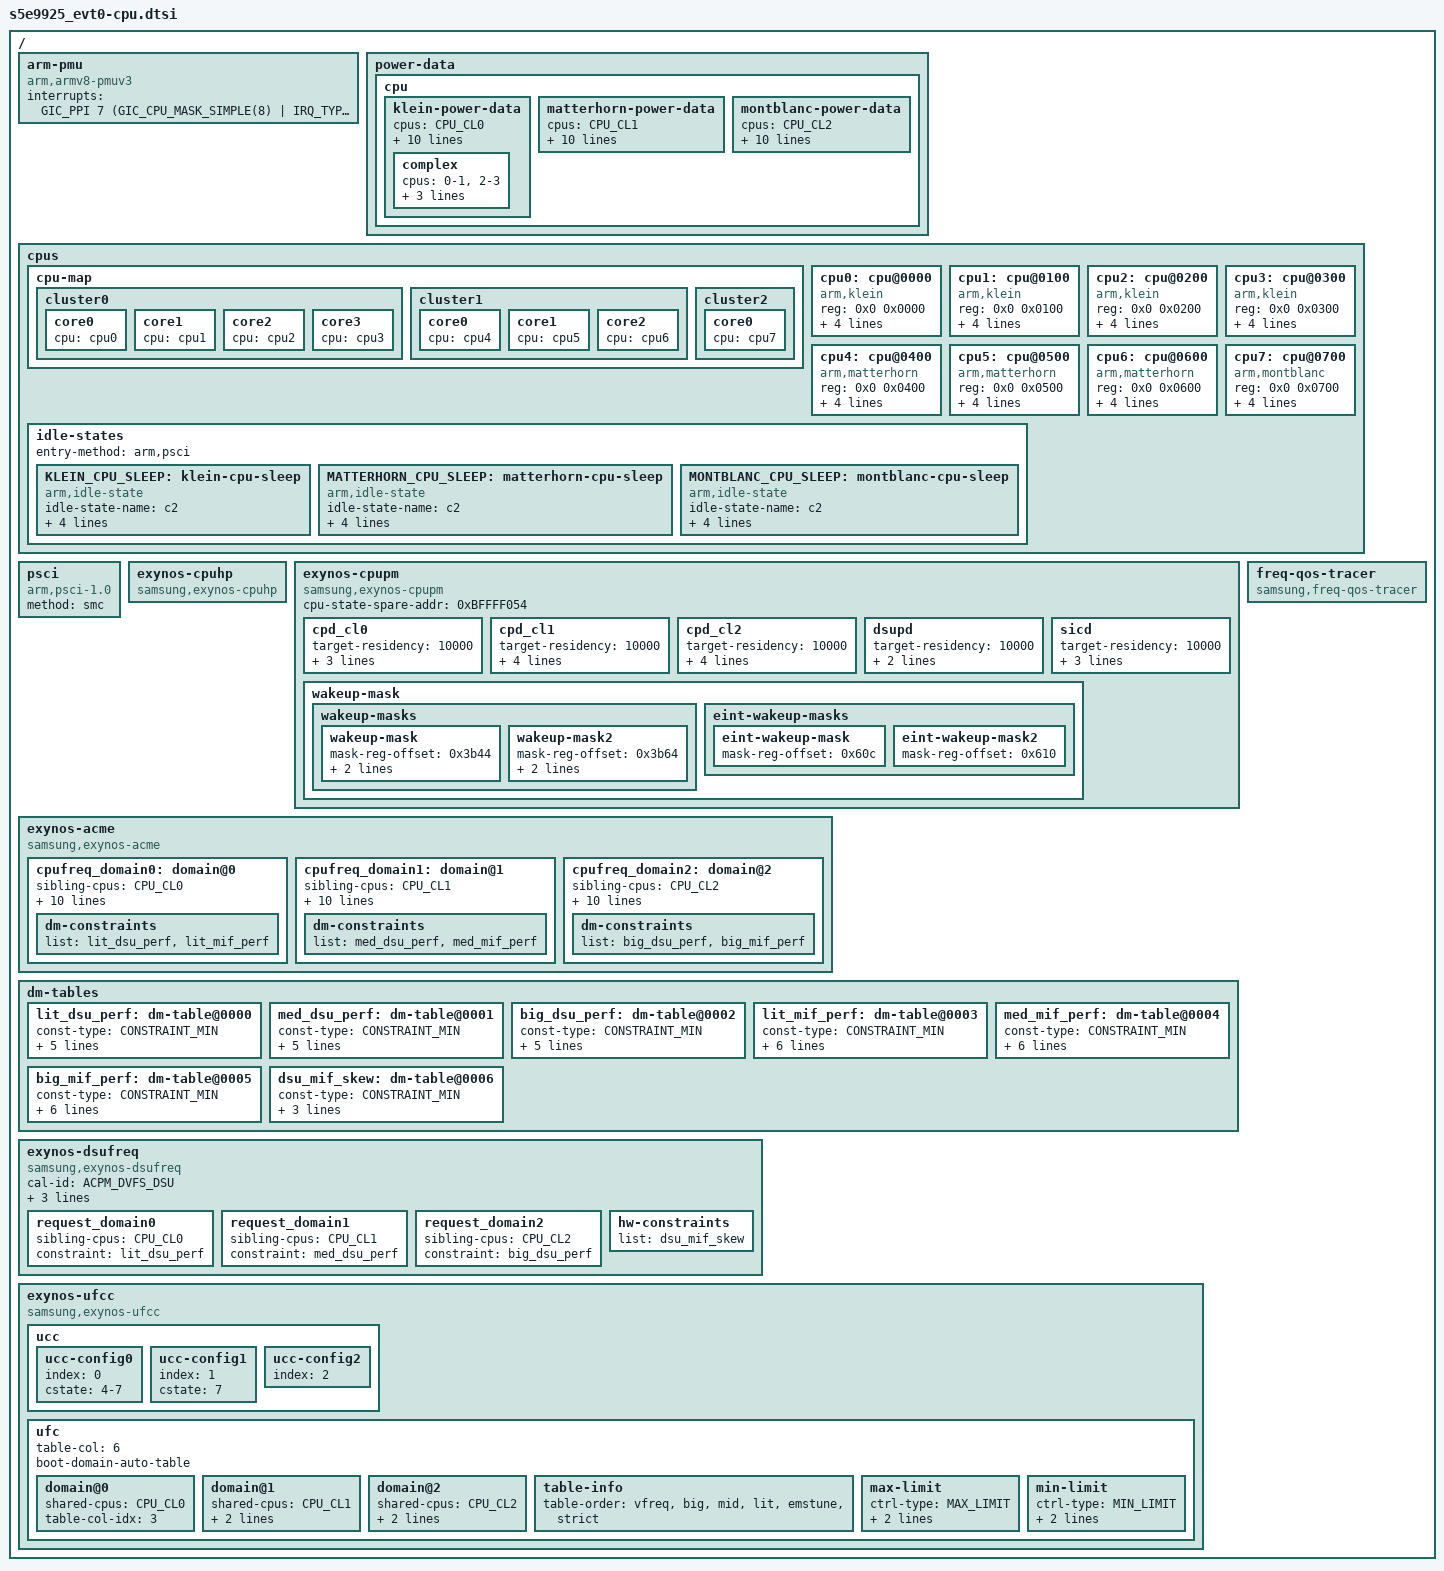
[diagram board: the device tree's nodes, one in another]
/*
 * SAMSUNG S5E9925 SoC CPU device tree source
 *
 * Copyright (c) 2020 Samsung Electronics Co., Ltd.
 *             http://www.samsung.com
 *
 * SAMSUNG EXYNOS9925 SoC device nodes are listed in this file.
 * EXYNOS based board files can include this file and provide
 * values for board specfic bindings.
 *
 * This program is free software; you can redistribute it and/or modify
 * it under the terms of the GNU General Public License version 2 as
 * published by the Free Software Foundation.
 */

#include <dt-bindings/soc/samsung/cpupm.h>

/ {
	arm-pmu {
		compatible = "arm,armv8-pmuv3";
		interrupts = <GIC_PPI 7 (GIC_CPU_MASK_SIMPLE(8) | IRQ_TYPE_LEVEL_HIGH)>;
	};

	#define CPU_CL0	"0-3"
	#define CPU_CL1	"4-6"
	#define CPU_CL2	"7"
	#define CPU_ALL	"0-7"

	power-data {
		#define CPUCL0_DMIPS_PER_MHZ 378
		#define CPUCL1_DMIPS_PER_MHZ 880
		#define CPUCL2_DMIPS_PER_MHZ 1005

		#define CPUCL0_DP_COEFF	188
		#define CPUCL1_DP_COEFF	482
		#define CPUCL2_DP_COEFF	710

		#define CPUCL0_SP_COEFF	62
		#define CPUCL1_SP_COEFF	234
		#define CPUCL2_SP_COEFF	537

		cpu {
			klein-power-data {
				/* default power data */
				cpus = CPU_CL0;
				capacity-dmips-mhz = <CPUCL0_DMIPS_PER_MHZ>;
				dynamic-power-coefficient = <CPUCL0_DP_COEFF>;
				static-power-coefficient = <CPUCL0_SP_COEFF>;

				/* dynamic power w/ ECT */
				ect-coeff-idx = <2>;

				/* precise static power */
				cal-id = <ACPM_DVFS_CPUCL0>;
				ect-param-vt = "DTM_LIT_VOLT_TEMP";
				ect-param-asv = "DTM_LIT_ASV";
				tz-name = "LITTLE";

				/* dhrystone to clang conversion ratio */
				dhry-to-clang-dp-ratio = <820>;
				dhry-to-clang-cap-ratio = <538>;

				complex {
					cpus = "0-1", "2-3";

					/* complex core/shared ratio */
					ect-param-cr = "COMPLEX_RATIO";
					ect-param-ccr = "COMPLEX_CORE_RATIO";
					ect-param-csr = "COMPLEX_SHARED_RATIO";
				};
			};
			matterhorn-power-data {
				/* default power data */
				cpus = CPU_CL1;
				capacity-dmips-mhz = <CPUCL1_DMIPS_PER_MHZ>;
				dynamic-power-coefficient = <CPUCL1_DP_COEFF>;
				static-power-coefficient = <CPUCL1_SP_COEFF>;

				/* dynamic power w/ ECT */
				ect-coeff-idx = <1>;

				/* precise static power */
				cal-id = <ACPM_DVFS_CPUCL1>;
				ect-param-vt = "DTM_MID_VOLT_TEMP";
				ect-param-asv = "DTM_MID_ASV";
				tz-name = "MID";

				/* dhrystone to clang conversion ratio */
				dhry-to-clang-dp-ratio = <820>;
				dhry-to-clang-cap-ratio = <377>;
			};
			montblanc-power-data {
				/* default power data */
				cpus = CPU_CL2;
				capacity-dmips-mhz = <CPUCL2_DMIPS_PER_MHZ>;
				dynamic-power-coefficient = <CPUCL2_DP_COEFF>;
				static-power-coefficient = <CPUCL2_SP_COEFF>;

				/* dynamic power w/ ECT */
				ect-coeff-idx = <0>;

				/* precise static power */
				cal-id = <ACPM_DVFS_CPUCL2>;
				ect-param-vt = "DTM_BIG_VOLT_TEMP";
				ect-param-asv = "DTM_BIG_ASV";
				tz-name = "BIG";

				/* dhrystone to clang conversion ratio */
				dhry-to-clang-dp-ratio = <820>;
				dhry-to-clang-cap-ratio = <385>;
			};
		};
	};

	cpus {
		#address-cells = <2>;
		#size-cells = <0>;

		cpu-map {
			cluster0 {
				core0 {
					cpu = <&cpu0>;
				};
				core1 {
					cpu = <&cpu1>;
				};
				core2 {
					cpu = <&cpu2>;
				};
				core3 {
					cpu = <&cpu3>;
				};
			};
			cluster1 {
				core0 {
					cpu = <&cpu4>;
				};
				core1 {
					cpu = <&cpu5>;
				};
				core2 {
					cpu = <&cpu6>;
				};
			};
			cluster2 {
				core0 {
					cpu = <&cpu7>;
				};
			};
		};

		cpu0: cpu@0000 {
			device_type = "cpu";
			compatible = "arm,klein", "arm,armv9";
			reg = <0x0 0x0000>;
			capacity-dmips-mhz = <CPUCL0_DMIPS_PER_MHZ>;
			dynamic-power-coefficient = <CPUCL0_DP_COEFF>;
			enable-method = "psci";
			cpu-idle-states =  <&KLEIN_CPU_SLEEP>;
		};
		cpu1: cpu@0100 {
			device_type = "cpu";
			compatible = "arm,klein", "arm,armv9";
			reg = <0x0 0x0100>;
			capacity-dmips-mhz = <CPUCL0_DMIPS_PER_MHZ>;
			dynamic-power-coefficient = <CPUCL0_DP_COEFF>;
			enable-method = "psci";
			cpu-idle-states =  <&KLEIN_CPU_SLEEP>;
		};
		cpu2: cpu@0200 {
			device_type = "cpu";
			compatible = "arm,klein", "arm,armv9";
			reg = <0x0 0x0200>;
			capacity-dmips-mhz = <CPUCL0_DMIPS_PER_MHZ>;
			dynamic-power-coefficient = <CPUCL0_DP_COEFF>;
			enable-method = "psci";
			cpu-idle-states =  <&KLEIN_CPU_SLEEP>;
		};
		cpu3: cpu@0300 {
			device_type = "cpu";
			compatible = "arm,klein", "arm,armv9";
			reg = <0x0 0x0300>;
			capacity-dmips-mhz = <CPUCL0_DMIPS_PER_MHZ>;
			dynamic-power-coefficient = <CPUCL0_DP_COEFF>;
			enable-method = "psci";
			cpu-idle-states =  <&KLEIN_CPU_SLEEP>;
		};
		cpu4: cpu@0400 {
			device_type = "cpu";
			compatible = "arm,matterhorn", "arm,armv9";
			reg = <0x0 0x0400>;
			capacity-dmips-mhz = <CPUCL1_DMIPS_PER_MHZ>;
			dynamic-power-coefficient = <CPUCL1_DP_COEFF>;
			enable-method = "psci";
			cpu-idle-states =  <&MATTERHORN_CPU_SLEEP>;
		};
		cpu5: cpu@0500 {
			device_type = "cpu";
			compatible = "arm,matterhorn", "arm,armv9";
			reg = <0x0 0x0500>;
			capacity-dmips-mhz = <CPUCL1_DMIPS_PER_MHZ>;
			dynamic-power-coefficient = <CPUCL1_DP_COEFF>;
			enable-method = "psci";
			cpu-idle-states =  <&MATTERHORN_CPU_SLEEP>;
		};
		cpu6: cpu@0600 {
			device_type = "cpu";
			compatible = "arm,matterhorn", "arm,armv9";
			reg = <0x0 0x0600>;
			capacity-dmips-mhz = <CPUCL1_DMIPS_PER_MHZ>;
			dynamic-power-coefficient = <CPUCL1_DP_COEFF>;
			enable-method = "psci";
			cpu-idle-states =  <&MATTERHORN_CPU_SLEEP>;
		};
		cpu7: cpu@0700 {
			device_type = "cpu";
			compatible = "arm,montblanc", "arm,armv9";
			reg = <0x0 0x0700>;
			capacity-dmips-mhz = <CPUCL2_DMIPS_PER_MHZ>;
			dynamic-power-coefficient = <CPUCL2_DP_COEFF>;
			enable-method = "psci";
			cpu-idle-states =  <&MONTBLANC_CPU_SLEEP>;
		};

		idle-states {
			entry-method = "arm,psci";

			KLEIN_CPU_SLEEP: klein-cpu-sleep {
				idle-state-name = "c2";
				compatible = "arm,idle-state";
				arm,psci-suspend-param = <0x0010000>;
				entry-latency-us = <70>;
				exit-latency-us = <160>;
				min-residency-us = <2000>;
				status = "okay";
			};

			MATTERHORN_CPU_SLEEP: matterhorn-cpu-sleep {
				idle-state-name = "c2";
				compatible = "arm,idle-state";
				arm,psci-suspend-param = <0x0010000>;
				entry-latency-us = <150>;
				exit-latency-us = <190>;
				min-residency-us = <2500>;
				status = "okay";
			};

			MONTBLANC_CPU_SLEEP: montblanc-cpu-sleep {
				idle-state-name = "c2";
				compatible = "arm,idle-state";
				arm,psci-suspend-param = <0x0010000>;
				entry-latency-us = <235>;
				exit-latency-us = <220>;
				min-residency-us = <3500>;
				status = "okay";
			};

		};

	};

	psci {
		compatible = "arm,psci-1.0";
		method = "smc";
	};

	exynos-cpuhp {
		compatible = "samsung,exynos-cpuhp";
		status = "okay";
	};

	exynos-cpupm {
		compatible = "samsung,exynos-cpupm";
		status = "okay";
		cpu-state-spare-addr = <0xBFFFF054>;

		cpd_cl0 {
			device_type ="cpupm";
			target-residency = <10000>;
			type = <POWERMODE_TYPE_CLUSTER>;
			cal-id = <0>;
			siblings = CPU_CL0;
		};

		cpd_cl1 {
			device_type = "cpupm";
			target-residency = <10000>;
			type = <POWERMODE_TYPE_CLUSTER>;
			cal-id = <1>;
			siblings = CPU_CL1;
			entry-allowed = CPU_CL1;
		};

		cpd_cl2 {
			device_type = "cpupm";
			target-residency = <10000>;
			type = <POWERMODE_TYPE_CLUSTER>;
			cal-id = <2>;
			siblings = CPU_CL2;
			entry-allowed = CPU_CL2;
		};

		dsupd {
			device_type = "cpupm";
			target-residency = <10000>;
			type = <POWERMODE_TYPE_DSU>;
			siblings = CPU_ALL;
		};

		sicd {
			device_type = "cpupm";
			target-residency = <10000>;
			type = <POWERMODE_TYPE_SYSTEM>;
			siblings = CPU_ALL;
			entry-allowed = CPU_ALL;
		};

		wakeup-mask {
			wakeup-masks {
				wakeup-mask {
					mask-reg-offset = <0x3b44>;
					stat-reg-offset = <0x3b50>;
					mask = <0xff000000>;
				};
				wakeup-mask2 {
					mask-reg-offset = <0x3b64>;
					stat-reg-offset = <0x3b54>;
					mask = <0x00>;
				};
			};

			eint-wakeup-masks {
				eint-wakeup-mask {
					mask-reg-offset = <0x60c>;
				};
				eint-wakeup-mask2 {
					mask-reg-offset = <0x610>;
				};
			};
		};
	};

	exynos-acme {
		compatible = "samsung,exynos-acme";
		status = "okay";

		cpufreq_domain0: domain@0 {
			sibling-cpus = CPU_CL0;
			cal-id = <ACPM_DVFS_CPUCL0>;
			dm-type = <DM_CPU_CL0>;

			max-freq = <2112000>;
			min-freq = <400000>;

			fast-switch;
			thread-run-on = "0-5";

			#cooling-cells = <2>; /* min followed by max */
			ect-coeff-index = <2>;
			tz-cooling-name = "LITTLE";

			freq-table = < 160000
				       267000
				       400000
				       576000
				       768000
				       960000
				      1152000
				      1344000
				      1536000
				      1728000
				      1920000
				      2112000
				      2304000
				      2400000
				      2516000
				      2612000 >;

			dm-constraints {
				list = <&lit_dsu_perf>,
					<&lit_mif_perf>;
			};
		};

		cpufreq_domain1: domain@1 {
			sibling-cpus = CPU_CL1;
			cal-id = <ACPM_DVFS_CPUCL1>;
			dm-type = <DM_CPU_CL1>;

			max-freq = <2880000>;
			min-freq = <576000>;

			fast-switch;
			thread-run-on = "0-5";

			#cooling-cells = <2>; /* min followed by max */
			ect-coeff-index = <1>;
			tz-cooling-name = "MID";

			freq-table = < 160000
				       267000
				       400000
				       576000
				       768000
				       960000
				      1152000
				      1344000
				      1536000
				      1728000
				      1920000
				      2112000
				      2304000
				      2496000
				      2688000
				      2880000
				      2912000
				      3015000
				      3111000
				      3207000 >;

			dm-constraints {
				list = <&med_dsu_perf>,
					<&med_mif_perf>;
			};
		};

		cpufreq_domain2: domain@2 {
			sibling-cpus = CPU_CL2;
			cal-id = <ACPM_DVFS_CPUCL2>;
			dm-type = <DM_CPU_CL2>;

			max-freq = <2912000>;
			min-freq = <576000>;

			fast-switch;
			thread-run-on = "0-5";

			#cooling-cells = <2>; /* min followed by max */
			ect-coeff-index = <0>;
			tz-cooling-name = "BIG";

			freq-table = < 160000
				       267000
				       400000
				       576000
				       768000
				       960000
				      1152000
				      1344000
				      1536000
				      1728000
				      1920000
				      2112000
				      2304000
				      2496000
				      2688000
				      2880000
				      2912000
				      3015000
				      3110000
				      3207000 >;

			dm-constraints {
				list = <&big_dsu_perf>,
					<&big_mif_perf>;
			};
		};
	};

	dm-tables {
		lit_dsu_perf: dm-table@0000 {
			const-type = <CONSTRAINT_MIN>;
			dm-slave = <DM_DSU>;
			master-cal-id = <ACPM_DVFS_CPUCL0>;
			slave-cal-id = <ACPM_DVFS_DSU>;

				/* CPU	  DSU */
			table = < 160000  160000
				  267000  160000
				  400000  267000
				  576000  267000
				  768000  480000
				  960000  672000
				 1152000  864000
				 1344000 1056000
				 1536000 1248000
				 1728000 1440000
				 1920000 1632000
				 2112000 1824000
				 2304000 2016000
				 2400000 2112000
				 2516000 2112000
				 2612000 2208000 >;
		};
		med_dsu_perf: dm-table@0001 {
			const-type = <CONSTRAINT_MIN>;
			dm-slave = <DM_DSU>;
			master-cal-id = <ACPM_DVFS_CPUCL1>;
			slave-cal-id = <ACPM_DVFS_DSU>;

				/* CPU	  DSU */
			table = < 160000  160000
				  267000  160000
				  400000  267000
				  576000  267000
				  768000  480000
				  960000  672000
				 1152000  864000
				 1344000  864000
				 1536000 1056000
				 1728000 1248000
				 1920000 1440000
				 2112000 1632000
				 2304000 1824000
				 2496000 2016000
				 2688000 2016000
				 2880000 2112000
				 3015000 2208000
				 3111000 2208000
				 3207000 2208000 >;
		};
		big_dsu_perf: dm-table@0002 {
			const-type = <CONSTRAINT_MIN>;
			dm-slave = <DM_DSU>;
			master-cal-id = <ACPM_DVFS_CPUCL2>;
			slave-cal-id = <ACPM_DVFS_DSU>;

				/* CPU	  DSU */
			table = < 166000  166000
				  267000  166000
				  400000  267000
				  576000  267000
				  768000  480000
				  960000  672000
				 1152000  672000
				 1248000  864000
				 1344000  864000
				 1536000 1056000
				 1728000 1248000
				 1920000 1440000
				 2112000 1632000
				 2304000 1632000
				 2496000 1824000
				 2688000 2016000
				 2880000 2112000
				 2912000 2112000
				 3015000 2208000
				 3110000 2208000
				 3207000 2208000 >;
		};
		lit_mif_perf: dm-table@0003 {
			const-type = <CONSTRAINT_MIN>;
			dm-slave = <DM_MIF>;
			master-cal-id = <ACPM_DVFS_CPUCL0>;
			slave-cal-id = <ACPM_DVFS_MIF>;
			dynamic-disable;

				/* CPU	  MIF */
			table = < 160000       0
				  267000       0
				  400000       0
				  576000       0
				  768000       0
				  960000       0
				 1152000       0
				 1344000       0
				 1536000       0
				 1728000       0
				 1920000       0
				 2112000       0
				 2304000       0
				 2400000       0
				 2516000       0
				 2612000       0 >;
		};
		med_mif_perf: dm-table@0004 {
			const-type = <CONSTRAINT_MIN>;
			dm-slave = <DM_MIF>;
			master-cal-id = <ACPM_DVFS_CPUCL1>;
			slave-cal-id = <ACPM_DVFS_MIF>;
			dynamic-disable;

				/* CPU	  MIF */
			table = < 160000       0
				  267000       0
				  400000       0
				  576000       0
				  768000       0
				  960000       0
				 1152000       0
				 1344000       0
				 1536000       0
				 1728000       0
				 1920000       0
				 2112000       0
				 2304000       0
				 2496000       0
				 2688000       0
				 2880000       0
				 3015000       0
				 3111000       0
				 3207000       0 >;
		};
		big_mif_perf: dm-table@0005 {
			const-type = <CONSTRAINT_MIN>;
			dm-slave = <DM_MIF>;
			master-cal-id = <ACPM_DVFS_CPUCL2>;
			slave-cal-id = <ACPM_DVFS_MIF>;
			dynamic-disable;

				/* CPU	  MIF */
			table = < 160000       0
				  267000       0
				  400000       0
				  576000       0
				  768000       0
				  960000       0
				 1152000       0
				 1344000       0
				 1536000       0
				 1728000       0
				 1920000       0
				 2112000       0
				 2304000       0
				 2496000       0
				 2688000       0
				 2880000       0
				 3015000       0
				 3110000       0
				 3207000       0 >;
		};
		dsu_mif_skew: dm-table@0006 {
			const-type = <CONSTRAINT_MIN>;
			dm-slave = <DM_MIF>;
			ect-name = "DSU_MIF";
			guidance;
		};
	};

	exynos-dsufreq {
		compatible = "samsung,exynos-dsufreq";
		status = "okay";

		cal-id = <ACPM_DVFS_DSU>;
		dm-type = <DM_DSU>;
		dss-type = <ESS_FLAG_DSU>;
		init-with-dt = <1>;

		request_domain0 {
			sibling-cpus = CPU_CL0;
			constraint = <&lit_dsu_perf>;
		};
		request_domain1 {
			sibling-cpus = CPU_CL1;
			constraint = <&med_dsu_perf>;
		};
		request_domain2 {
			sibling-cpus = CPU_CL2;
			constraint = <&big_dsu_perf>;
		};
		hw-constraints {
			list = <&dsu_mif_skew>;
		};
	};

	exynos-ufcc {
		compatible = "samsung,exynos-ufcc";
		status = "okay";

		ucc {
			ucc-config0 {
				index = <0>;
				cstate = "4-7";
			};
			ucc-config1 {
				index = <1>;
				cstate = "7";
			};
			ucc-config2 {
				index = <2>;
			};
		};

		ufc {
			/* Ctrl Type */
			#define MIN_LIMIT		0
			#define MIN_LIMIT_WO_BOOST	1
			#define MAX_LIMIT		2

			table-col = <6>;
			boot-domain-auto-table;

			domain@0 {
				device_type = "ufc-domain";
				shared-cpus = CPU_CL0;
				table-col-idx = <3>;
			};
			domain@1 {
				device_type = "ufc-domain";
				shared-cpus = CPU_CL1;
				table-col-idx = <2>;
				allow-disable-cpus;
			};
			domain@2 {
				device_type = "ufc-domain";
				shared-cpus = CPU_CL2;
				table-col-idx = <1>;
				allow-disable-cpus;
			};

			table-info {
				table-order = "vfreq",
					"big",
					"mid",
					"lit",
					"emstune",
					"strict";
			};

			max-limit {
				device_type = "ufc-table";
				ctrl-type = <MAX_LIMIT>;

				table = < 3207000 3207000 3207000 2304000 0 0
					  3111000 3111000 3111000 2304000 0 0
					  3015000 3015000 3015000 2304000 0 0
					  2912000 2912000 2912000 2304000 0 0
					  2880000 2880000 2880000 2304000 0 0
					  2688000 2688000 2688000 2304000 0 0
					  2496000 2496000 2496000 2304000 0 0
					  2304000 2304000 2304000 2304000 0 0
					  2112000 2112000 2112000 2304000 0 0
					  1920000 1920000 1920000 2304000 0 0
					  1728000 1728000 1728000 2112000 0 0
					  1536000 1536000 1536000 1920000 0 0
					  1344000 1344000 1344000 1728000 0 0
					  1152000 1152000 1152000 1536000 0 0
					   960000  960000  960000 1344000 0 0
					   768000  768000  768000 1152000 0 0
					   576000  576000  576000 1152000 0 0
					   400000  400000  400000 1152000 0 0 >;
					  /* fill little freq automatically */
			};
			min-limit {
				device_type = "ufc-table";
				ctrl-type = <MIN_LIMIT>;

				table = < 3207000 3207000 3207000 2612000 2 1
					  3111000 3111000 3111000 2612000 2 1
					  3015000 3015000 3015000 2612000 2 1
					  2912000 2912000 2912000 2612000 2 1
					  2880000 2880000 2880000 2612000 2 1
					  2688000 2688000 2688000 2612000 2 1
					  2496000 2496000 2496000 2612000 2 1
					  2304000 2304000 2304000 2612000 2 1
					  2112000 2112000 2112000  768000 1 1
					  1920000 1920000 1920000  768000 1 1
					  1728000 1728000 1728000  768000 1 1
					  1536000 1536000 1536000  768000 1 1
					  1344000 1344000 1344000  768000 1 1
					  1152000 1152000 1152000  768000 1 1
					   960000  960000  960000  768000 1 1
					   768000  768000  768000  768000 0 1
					   576000  576000  576000  768000 0 1
					   400000  400000  400000  768000 0 1 >;
					  /* fill little freq automatically */
			};
		};
	};

	freq-qos-tracer {
		compatible = "samsung,freq-qos-tracer";
		status = "okay";
	};

};

